# GD32H71x_72x register map
File version: 1.0
CPU: CM7 r1p2, little endian, MPU, FPU, 4 interrupt priority bits
Registers are 32-bit, read-write, reset 0x0 unless marked. A register's access mark holds for its fields unless they carry their own. Offsets are from the block's base; [hi:lo] are bit positions; {n}, {i} and the like mark numbered series; 'fields as' and 'values as' point back to an identical list.

## EFUSE — Electronic fuse
Base 0x40022800
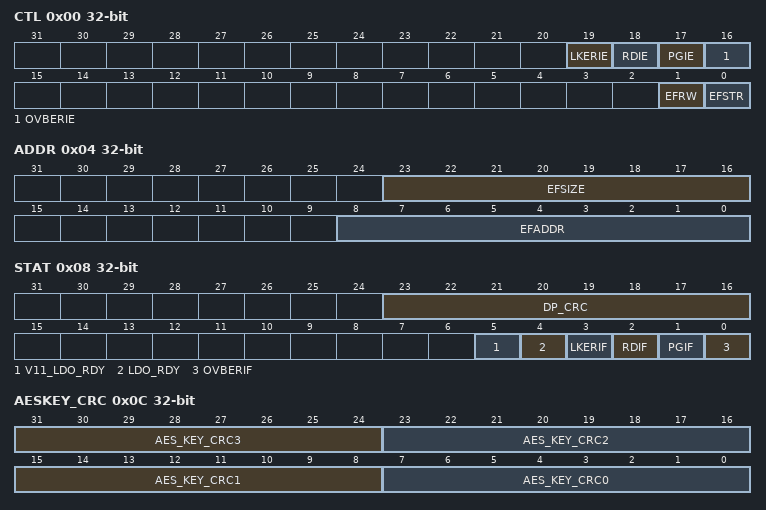
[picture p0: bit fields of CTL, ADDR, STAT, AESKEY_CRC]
0x00 CTL — Control register
  [19] LKERIE — Writing after lock error interrupt enable
  [18] RDIE — Read completed interrupt enable
  [17] PGIE — Program completed interrupt enable
  [16] OVBERIE — Overstep boundary error interrupt enable
  [1] EFRW — The selection of EFUSE operation
  [0] EFSTR — Start EFUSE operation
0x04 ADDR — Address register
  [23:16] EFSIZE — Read or write EFUSE data size
  [8:0] EFADDR — Read or write EFUSE data start address
0x08 STAT access per field — Status register
  [23:16] DP_CRC ro — 8-bits CRC calculation result value of debug password data
  [5] V11_LDO_RDY ro — EFUSE 1.1V LDO ready signal
  [4] LDO_RDY ro — EFUSE 2.5V LDO ready signal
  [3] LKERIF rw — Writing after lock error interrupt flag
  [2] RDIF rw — Read completed flag
  [1] PGIF rw — Program completed flag
  [0] OVBERIF rw — Overstep boundary error interrupt flag
0x0C AESKEY_CRC ro
  [31:24] AES_KEY_CRC3 — Refer to the description of AES_KEY_CRC1[7:0].
  [23:16] AES_KEY_CRC2 — Refer to the description of AES_KEY_CRC1[7:0].
  [15:8] AES_KEY_CRC1 — Refer to the description of AES_KEY_CRC1[7:0].
  [7:0] AES_KEY_CRC0 — 8-bits CRC calculation result value of AES key bits
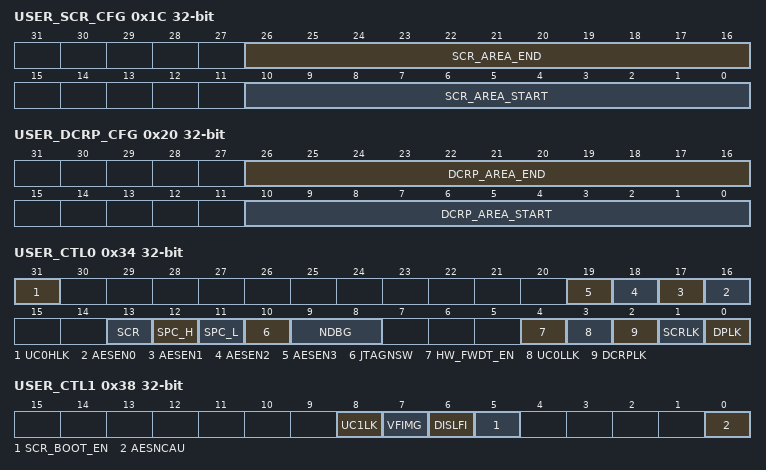
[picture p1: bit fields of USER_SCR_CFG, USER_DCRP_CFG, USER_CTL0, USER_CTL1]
0x1C USER_SCR_CFG — User SCR configuration register
  [26:16] SCR_AREA_END — Secure user area end address status bits
  [10:0] SCR_AREA_START — Secure user area start address status bits
0x20 USER_DCRP_CFG — User DCRP configuration register
  [26:16] DCRP_AREA_END — DCRP area end address configuration bits
  [10:0] DCRP_AREA_START — DCRP area start address configuration bits
{0x24+4i} USER_DATA_LK{i} (i=0..3) — User data lock regist {i}
  [31:0] UDLK — The hash of the public key and the user data register lock bit, correspond to 1 bit lock per byte, and once locked, it becomes non-writable.
0x34 USER_CTL0 — User control register 0
  [31] UC0HLK — EFUSE_USER_CTL0 register high 31-16 lock bit
  [n+16] AESEN{n} (n=0..3) — Lock EFUSE_AES_KEY register and enable AES decrypt function
  [13] SCR — Secure mode enable
  [12] SPC_H — Configure security protection to level high
  [11] SPC_L — Configure security protection to level low
  [10] JTAGNSW — SW or JTAG debugger select
  [9:8] NDBG — Debugging permission setting
  [4] HW_FWDT_EN — Hardware FWDGT enable
  [3] UC0LLK — EFUSE_USER_CTL0 register low 15-0 lock bit
  [2] DCRPLK — DCRP area address lock bit
  [1] SCRLK — Secure user area address lock bit
  [0] DPLK — EFUSE_DPx register lock bit
0x38 USER_CTL1 — User control register 1
  [8] UC1LK — EFUSE_USER_CTL1 register 31-0 lock bit
  [7] VFIMG — Firmware image verification enable bit
  [6] DISLFI — Licensed firmware install ( LFI ) disable
  [5] SCR_BOOT_EN — Secure boot enable
  [0] AESNCAU — AES key for cau configuration bit
0x44 DP0 wo — Debug password regist 0
  [31:0] DP — EFUSE Debug password value.
0x48 DP1 wo — Debug password regist 1
  [31:0] DP — EFUSE Debug password value.
{0x4C+0x20*i} AES_KEY{i:02} wo (i=0..3) — Firmware AES key register
  [31:0] AESKEY — EFUSE AES key value.
0x50 AES_KEY10 wo — Firmware AES key register
  [31:0] AESKEY — EFUSE AES key value.
0x54 AES_KEY20 wo — Firmware AES key register
  [31:0] AESKEY — EFUSE AES key value.
0x58 AES_KEY30 wo — Firmware AES key register
  [31:0] AESKEY — EFUSE AES key value.
0x5C AES_KEY40 wo — Firmware AES key register
  [31:0] AESKEY — EFUSE AES key value.
0x60 AES_KEY50 wo — Firmware AES key register
  [31:0] AESKEY — EFUSE AES key value.
0x64 AES_KEY60 wo — Firmware AES key register
  [31:0] AESKEY — EFUSE AES key value.
0x68 AES_KEY70 wo — Firmware AES key register
  [31:0] AESKEY — EFUSE AES key value.
0x70 AES_KEY11 wo — Firmware AES key register
  [31:0] AESKEY — EFUSE AES key value.
0x74 AES_KEY21 wo — Firmware AES key register
  [31:0] AESKEY — EFUSE AES key value.
0x78 AES_KEY31 wo — Firmware AES key register
  [31:0] AESKEY — EFUSE AES key value.
0x7C AES_KEY41 wo — Firmware AES key register
  [31:0] AESKEY — EFUSE AES key value.
0x80 AES_KEY51 wo — Firmware AES key register
  [31:0] AESKEY — EFUSE AES key value.
0x84 AES_KEY61 wo — Firmware AES key register
  [31:0] AESKEY — EFUSE AES key value.
0x88 AES_KEY71 wo — Firmware AES key register
  [31:0] AESKEY — EFUSE AES key value.
0x90 AES_KEY12 wo — Firmware AES key register
  [31:0] AESKEY — EFUSE AES key value.
0x94 AES_KEY22 wo — Firmware AES key register
  [31:0] AESKEY — EFUSE AES key value.
0x98 AES_KEY32 wo — Firmware AES key register
  [31:0] AESKEY — EFUSE AES key value.
0x9C AES_KEY42 wo — Firmware AES key register
  [31:0] AESKEY — EFUSE AES key value.
0xA0 AES_KEY52 wo — Firmware AES key register
  [31:0] AESKEY — EFUSE AES key value.
0xA4 AES_KEY62 wo — Firmware AES key register
  [31:0] AESKEY — EFUSE AES key value.
0xA8 AES_KEY72 wo — Firmware AES key register
  [31:0] AESKEY — EFUSE AES key value.
0xB0 AES_KEY13 wo — Firmware AES key register
  [31:0] AESKEY — EFUSE AES key value.
0xB4 AES_KEY23 wo — Firmware AES key register
  [31:0] AESKEY — EFUSE AES key value.
0xB8 AES_KEY33 wo — Firmware AES key register
  [31:0] AESKEY — EFUSE AES key value.
0xBC AES_KEY43 wo — Firmware AES key register
  [31:0] AESKEY — EFUSE AES key value.
0xC0 AES_KEY53 wo — Firmware AES key register
  [31:0] AESKEY — EFUSE AES key value.
0xC4 AES_KEY63 wo — Firmware AES key register
  [31:0] AESKEY — EFUSE AES key value.
0xC8 AES_KEY73 wo — Firmware AES key register
  [31:0] AESKEY — EFUSE AES key value.
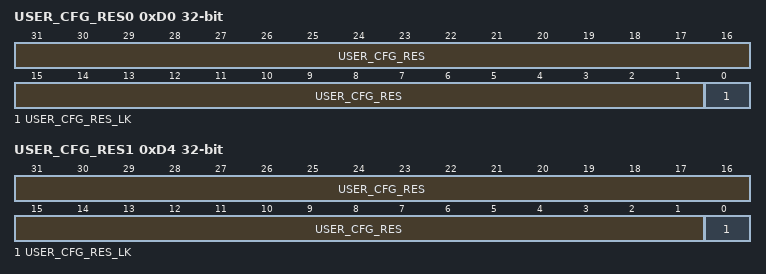
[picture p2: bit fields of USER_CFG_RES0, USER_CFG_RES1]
0xD0 USER_CFG_RES0 — User configuration reserved register 0
  [31:1] USER_CFG_RES — Dummy reg, must be kept at reset value.
  [0] USER_CFG_RES_LK — USER_CFG_RES register lock bit, bit63-0 lock
0xD4 USER_CFG_RES1 — User configuration reserved register 1
  fields as USER_CFG_RES0
{0xD8+4i} HASH_PUB_KEY{i} (i=0..15) — Hash public KEY regist {i}
  [31:0] HASH_PUB_KEY — Hash of public key value for secure boot function.
{0x118+4i} USER_DATA{i} (i=0..15) — User data register {i}
  [31:0] USERDATA — EFUSE USER_DATA value.
{0x168+4i} PUID{i} ro (i=0..2) — Product UID regist {i}
  [31:0] UID — EFUSE MCU UID value.
